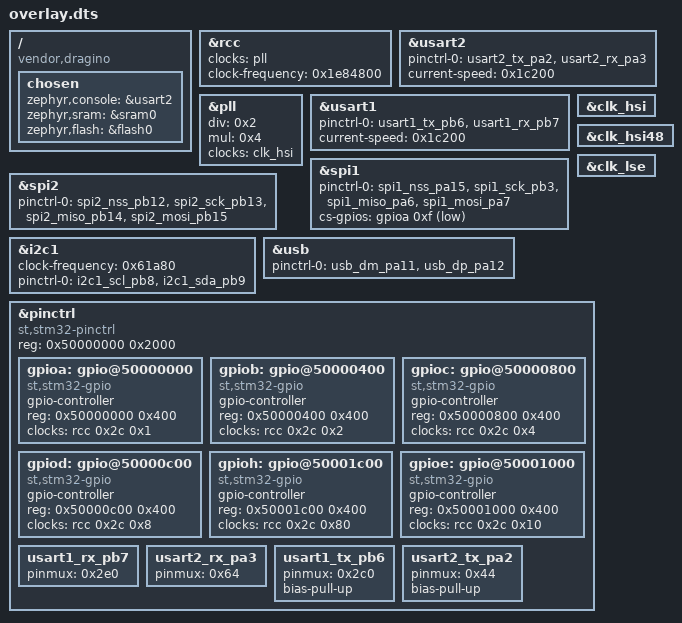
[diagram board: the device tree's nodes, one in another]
/ {
	compatible = "vendor,dragino";
	chosen {
		zephyr,console = &usart2;
		zephyr,sram = &sram0;
		zephyr,flash = &flash0;
	};
};
&rcc{
	clocks = < &pll >;
	clock-frequency = < 0x1e84800 >;
};
&usart2{
	status = "okay";
	pinctrl-0 = < &usart2_tx_pa2 &usart2_rx_pa3 >;
	pinctrl-names = "default";
	current-speed = < 0x1c200 >;
};
&pll{
	status = "okay";
	div = < 0x2 >;
	mul = < 0x4 >;
	clocks = < &clk_hsi >;
};
&usart1{
	status = "okay";
	pinctrl-0 = < &usart1_tx_pb6 &usart1_rx_pb7 >;
	pinctrl-names = "default";
	current-speed = < 0x1c200 >;
};
&clk_hsi{
	status = "okay";
};
&spi1{
	status = "okay";
	pinctrl-0 = < &spi1_nss_pa15 &spi1_sck_pb3 &spi1_miso_pa6 &spi1_mosi_pa7 >;
	pinctrl-names = "default";
	cs-gpios = < &gpioa 0xf 0x1 >;
};
&clk_hsi48{
	status = "okay";
};
&spi2{
	status = "okay";
	pinctrl-0 = < &spi2_nss_pb12 &spi2_sck_pb13 &spi2_miso_pb14 &spi2_mosi_pb15 >;
	pinctrl-names = "default";
};
&i2c1{
	clock-frequency = < 0x61a80 >;
	status = "okay";
	pinctrl-0 = < &i2c1_scl_pb8 &i2c1_sda_pb9 >;
	pinctrl-names = "default";
};
&usb{
	status = "okay";
	pinctrl-0 = < &usb_dm_pa11 &usb_dp_pa12 >;
	pinctrl-names = "default";
};
&clk_lse{
	status = "okay";
};
&pinctrl{
	compatible = "st,stm32-pinctrl";
	#address-cells = < 0x1 >;
	#size-cells = < 0x1 >;
	reg = < 0x50000000 0x2000 >;
	gpioa: gpio@50000000 {
		compatible = "st,stm32-gpio";
		gpio-controller;
		#gpio-cells = < 0x2 >;
		reg = < 0x50000000 0x400 >;
		clocks = < &rcc 0x2c 0x1 >;
	};
	gpiob: gpio@50000400 {
		compatible = "st,stm32-gpio";
		gpio-controller;
		#gpio-cells = < 0x2 >;
		reg = < 0x50000400 0x400 >;
		clocks = < &rcc 0x2c 0x2 >;
	};
	gpioc: gpio@50000800 {
		compatible = "st,stm32-gpio";
		gpio-controller;
		#gpio-cells = < 0x2 >;
		reg = < 0x50000800 0x400 >;
		clocks = < &rcc 0x2c 0x4 >;
	};
	gpiod: gpio@50000c00 {
		compatible = "st,stm32-gpio";
		gpio-controller;
		#gpio-cells = < 0x2 >;
		reg = < 0x50000c00 0x400 >;
		clocks = < &rcc 0x2c 0x8 >;
	};
	gpioh: gpio@50001c00 {
		compatible = "st,stm32-gpio";
		gpio-controller;
		#gpio-cells = < 0x2 >;
		reg = < 0x50001c00 0x400 >;
		clocks = < &rcc 0x2c 0x80 >;
	};
	gpioe: gpio@50001000 {
		compatible = "st,stm32-gpio";
		gpio-controller;
		#gpio-cells = < 0x2 >;
		reg = < 0x50001000 0x400 >;
		clocks = < &rcc 0x2c 0x10 >;
	};
	usart1_rx_pb7: usart1_rx_pb7 {
		pinmux = < 0x2e0 >;
	};
	usart2_rx_pa3: usart2_rx_pa3 {
		pinmux = < 0x64 >;
	};
	usart1_tx_pb6: usart1_tx_pb6 {
		pinmux = < 0x2c0 >;
		bias-pull-up;
	};
	usart2_tx_pa2: usart2_tx_pa2 {
		pinmux = < 0x44 >;
		bias-pull-up;
	};
};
